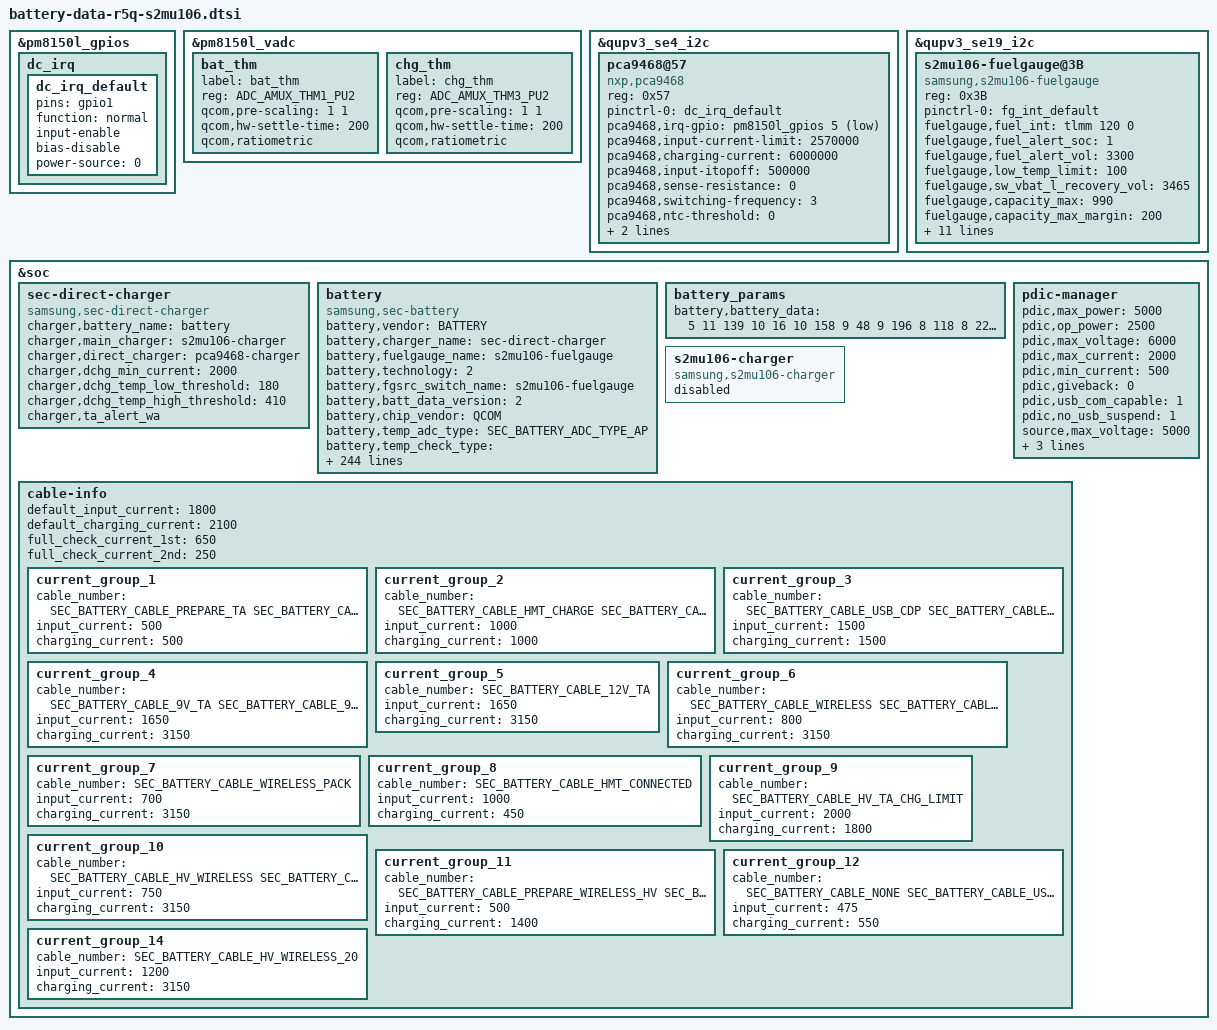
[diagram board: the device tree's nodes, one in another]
/* Copyright (c) 2014, The Linux Foundation. All rights reserved.
 *
 * This program is free software; you can redistribute it and/or modify
 * it under the terms of the GNU General Public License version 2 and
 * only version 2 as published by the Free Software Foundation.
 *
 * This program is distributed in the hope that it will be useful,
 * but WITHOUT ANY WARRANTY; without even the implied warranty of
 * MERCHANTABILITY or FITNESS FOR A PARTICULAR PURPOSE.  See the
 * GNU General Public License for more details.
 */

#include <dt-bindings/battery/sec_battery_param_define.h>

&pm8150l_gpios {
	dc_irq { /* DC_IRQ_N */
		dc_irq_default: dc_irq_default {
			pins = "gpio1";
			function = "normal";
			input-enable;
			bias-disable;
			power-source = <0>;
		};
	};
};

&pm8150l_vadc {
	bat_thm { /* AMUX_1 */
		label = "bat_thm";
		reg = <ADC_AMUX_THM1_PU2>;
		qcom,pre-scaling = <1 1>;
		qcom,hw-settle-time = <200>;
		qcom,ratiometric;
	};
	chg_thm { /* AMUX_3 */
		label = "chg_thm";
		reg = <ADC_AMUX_THM3_PU2>;
		qcom,pre-scaling = <1 1>;
		qcom,hw-settle-time = <200>;
		qcom,ratiometric;
	};
};

&qupv3_se4_i2c {
	status = "okay";

	pca9468@57 {
		compatible = "nxp,pca9468";
		reg = <0x57>;
		pinctrl-names = "default";
		pinctrl-0 = <&dc_irq_default>;

		pca9468,irq-gpio = <&pm8150l_gpios 5 GPIO_ACTIVE_LOW>; /* DC_IRQ */
		pca9468,input-current-limit = <2570000>; /* 2.57A */
		pca9468,charging-current = <6000000>; /* 6A */
		pca9468,input-itopoff = <500000>; /* 500mA */
		pca9468,sense-resistance = <0>; /* 5mOhm */
		pca9468,switching-frequency = <3>; /* 980KHz */
		pca9468,ntc-threshold = <0>; /* disable */
		pca9468,chg_gpio_en = <&pm8150l_gpios 2 0>; /* DC_CPEN */
		pca9468,ta-mode = <1>; /* 2:1 charging mode */
	};
};

&qupv3_se19_i2c {
	status = "ok";

	s2mu106-fuelgauge@3B {
		compatible = "samsung,s2mu106-fuelgauge";
		reg = <0x3B>;
		pinctrl-names = "default";
		pinctrl-0 = <&fg_int_default>;
		fuelgauge,fuel_int = <&tlmm 120 0>;
		fuelgauge,fuel_alert_soc = <1>;
		fuelgauge,fuel_alert_vol = <3300>;
		fuelgauge,low_temp_limit = <100>;
		fuelgauge,sw_vbat_l_recovery_vol = <3465>;
		fuelgauge,capacity_max = <990>;
		fuelgauge,capacity_max_margin = <200>;
		fuelgauge,capacity_min = <0>;
		fuelgauge,capacity_calculation_type = <28>;
		fuelgauge,capacity_full = <4370>;
		fuelgauge,type_str = "SDI";
		fuelgauge,fg_log_enable = <1>;
		fuelgauge,low_voltage_limit_lowtemp = <3100>;
		fuelgauge,i_socr_coeff = <80>;
		fuelgauge,low_t_compen_coeff = <180>;

		fuelgauge,ttf_capacity = <4370>;
		fuelgauge,cv_data = <
			2488	829	1809
			2409	832	1796
			2327	837	1769
			2272	840	1743
			2182	846	1721
			2104	850	1690
			2038	854	1670
			1950	859	1640
			1904	861	1622
			1838	865	1594
			1797	867	1576
			1749	870	1560
			1703	873	1531
			1683	873	1525
			1667	875	1515
			1660	875	1512
			1653	876	1509
			1615	878	1502
			1580	880	1483
			1553	881	1463
			1544	882	1458
			1520	883	1451
			1477	886	1424
			1431	888	1409
			1396	891	1383
			1347	894	1361
			1299	896	1332
			1267	898	1315
			1231	902	1288
			1202	904	1263
			1148	906	1243
			1109	909	1213
			1067	911	1185
			1031	914	1156
			1013	915	1140
			975	917	1111
			961	919	1084
			921	921	1064
			892	923	1038
			887	923	1019
			863	925	1004
			833	927	976
			808	929	946
			787	930	918
			780	931	904
			764	932	895
			744	934	864
			730	935	846
			715	936	828
			693	937	800
			681	938	783
			666	940	752
			651	941	735
			640	942	712
			628	945	697
			622	946	679
			618	947	664
			600	950	646
			596	951	627
			589	953	614
			584	953	601
			576	956	572
			577	957	553
			562	958	535
			511	968	506
			505	969	487
			493	971	464
			492	972	435
			484	973	417
			480	975	398
			474	976	380
			470	977	364
			462	977	355
			456	978	336
			452	979	329
			446	981	303
			437	982	282
			429	984	255
			423	985	242
			422	986	229
			414	987	211
			411	988	199
			405	989	191
			397	990	171
			391	991	140
			387	992	126
			384	993	107
			372	995	84
			364	997	54
			356	998	26
			356	998	13
			0	1000	0
			>;
	};
};

&soc {
	sec-direct-charger {
		status = "okay";
		compatible = "samsung,sec-direct-charger";

		charger,battery_name = "battery";
		charger,main_charger = "s2mu106-charger";
		charger,direct_charger = "pca9468-charger";

		charger,dchg_min_current = <2000>;
		charger,dchg_temp_low_threshold = <180>;
		charger,dchg_temp_high_threshold = <410>;

		charger,ta_alert_wa;
	};

	battery {
		status = "okay";
		compatible = "samsung,sec-battery";
		pinctrl-names = "default";
		battery,vendor = "BATTERY";
		battery,charger_name = "sec-direct-charger";
		battery,fuelgauge_name = "s2mu106-fuelgauge";
		battery,technology = <2>; /* POWER_SUPPLY_TECHNOLOGY_LION */
		battery,fgsrc_switch_name = "s2mu106-fuelgauge"; /* Fuelgauge voltage source */

		battery,batt_data_version = <2>;

		battery,chip_vendor = "QCOM";
		battery,temp_adc_type = <SEC_BATTERY_ADC_TYPE_AP>;

		battery,temp_check_type = <SEC_BATTERY_TEMP_CHECK_ADC>;
		battery,usb_temp_check_type = <SEC_BATTERY_TEMP_CHECK_NONE>;
		battery,chg_temp_check_type = <SEC_BATTERY_TEMP_CHECK_ADC>;
		battery,wpc_temp_check_type = <SEC_BATTERY_TEMP_CHECK_NONE>;
		battery,dchg_temp_check_type = <SEC_BATTERY_TEMP_CHECK_ADC>;

		battery,thermal_source = <SEC_BATTERY_THERMAL_SOURCE_ADC>;
		battery,usb_thermal_source = <SEC_BATTERY_THERMAL_SOURCE_ADC>;
		battery,chg_thermal_source = <SEC_BATTERY_THERMAL_SOURCE_ADC>;
		battery,wpc_thermal_source = <SEC_BATTERY_THERMAL_SOURCE_ADC>;
		battery,dchg_thermal_source = <SEC_BATTERY_THERMAL_SOURCE_CHG_ADC>;

		battery,polling_time = <10 30 30 30 3600>;

		battery,temp_table_adc = <250021 290527 319506 370285 427378
						492246 564673 645166 732968 825659
						924340 1024967 1126957 1226048 1321129
						1408985 1488245 1558510 1618036 1668566
						1708520 1740765 1750929>;
		battery,temp_table_data = <900 850 800 750 700
						650 600 550 500 450
						400 350 300 250 200
						150 100 50 0 (-50)
						(-100) (-150) (-200)>;

		battery,usb_temp_table_adc = <128092 155146 181746 212586 249610
						293641 346668 396929 460315 531033
						612607 708866 815008 922383 1030341
						1141067 1248355 1350324 1446150 1530838
						1604346 1665116 1714272>;
		battery,usb_temp_table_data = <900 850 800 750 700
						650 600 550 500 450
						400 350 300 250 200
						150 100 50 0 (-50)
						(-100) (-150) (-200)>;

		battery,chg_temp_table_adc = <107508 131686 159118 188746 223508
						262961 307691 361916 429577 488076
						586007 680146 775042 886814 995479
						1077371 1208541 1306638 1413804 1506271
						1581235 1644636 1687932>;
		battery,chg_temp_table_data = <900 850 800 750 700
						650 600 550 500 450
						400 350 300 250 200
						150 100 50 0 (-50)
						(-100) (-150) (-200)>;

		battery,wpc_temp_table_adc = <129022 155579 182115 213192 249978
						294052 346625 396929 460683 530860
						612175 708282 814035 921474 1028914
						1139553 1246214 1348248 1443900 1528741
						1602248 1661591 1712499>;
		battery,wpc_temp_table_data = <900 850 800 750 700
						650 600 550 500 450
						400 350 300 250 200
						150 100 50 0 (-50)
						(-100) (-150) (-200)>;

		battery,dchg_temp_table_adc = <110882 138414 166566 194718 234600
						276828 326094 387090 448086 525504
						607614 696762 792948 893826 999396
						1107312 1210536 1304376 1393524 1473288
						1543668 1602318 1651584>;
		battery,dchg_temp_table_data = <900 850 800 750 700
						650 600 550 500 450
						400 350 300 250 200
						150 100 50 0 (-50)
						(-100) (-150) (-200)>;

		battery,wireless_cc_cv = <85>;
		battery,wpc_det = <&pm8150l_gpios 1 GPIO_ACTIVE_HIGH>; /* WPC_DET */
		battery,wpc_en = <&expander_gpios 3 0>; /* WPC_EN */
		battery,adc_check_count = <5>;

		battery,cable_check_type = <SEC_BATTERY_CABLE_CHECK_PSY>;
		battery,cable_source_type = <SEC_BATTERY_CABLE_SOURCE_EXTERNAL>;
		battery,polling_type = <SEC_BATTERY_MONITOR_ALARM>;
		battery,monitor_initial_count = <0>;

		battery,battery_check_type = <0>; /* SEC_BATTERY_CHECK_NONE */
		battery,check_count = <0>;
		battery,check_adc_max = <1440>;
		battery,check_adc_min = <0>;

		battery,ovp_uvlo_check_type = <SEC_BATTERY_OVP_UVLO_CHGPOLLING>;

		battery,temp_check_count = <1>;
		battery,temp_highlimit_threshold_event = <700>;
		battery,temp_highlimit_recovery_event = <680>;
		battery,temp_high_threshold_event = <500>;
		battery,temp_high_recovery_event = <480>;
		battery,temp_low_threshold_event = <0>;
		battery,temp_low_recovery_event = <20>;
		battery,temp_highlimit_threshold_normal = <700>;
		battery,temp_highlimit_recovery_normal = <680>;
		battery,temp_high_threshold_normal = <500>;
		battery,temp_high_recovery_normal = <480>;
		battery,temp_low_threshold_normal = <0>;
		battery,temp_low_recovery_normal = <20>;
		battery,temp_highlimit_threshold_lpm = <700>;
		battery,temp_highlimit_recovery_lpm = <680>;
		battery,temp_high_threshold_lpm = <500>;
		battery,temp_high_recovery_lpm = <480>;
		battery,temp_low_threshold_lpm = <0>;
		battery,temp_low_recovery_lpm = <20>;
		battery,wpc_high_threshold_normal = <450>;
		battery,wpc_high_recovery_normal = <430>;
		battery,wpc_low_threshold_normal = <0>;
		battery,wpc_low_recovery_normal = <20>;
		battery,tx_high_threshold = <450>;
		battery,tx_high_recovery = <400>;
		battery,tx_low_threshold = <0>;
		battery,tx_low_recovery = <50>;
		battery,full_check_type = <SEC_BATTERY_FULLCHARGED_FG_CURRENT>;
		battery,full_check_type_2nd = <SEC_BATTERY_FULLCHARGED_FG_CURRENT>;
		battery,full_check_count = <1>;
		battery,chg_gpio_full_check = <0>;
		battery,chg_polarity_full_check = <1>;

		battery,chg_high_temp = <460>;
		battery,chg_high_temp_recovery = <440>;
		battery,dchg_high_temp = <560>;
		battery,dchg_high_temp_recovery = <400>;
		battery,dchg_high_batt_temp = <400>;
		battery,dchg_high_batt_temp_recovery = <380>;
		battery,chg_input_limit_current = <1000>;
		battery,chg_charging_limit_current = <1700>;
		battery,dchg_input_limit_current = <1000>;
		battery,dchg_charging_limit_current = <2000>;

		battery,wpc_temp_control_source = <TEMP_CONTROL_SOURCE_BAT_THM>;
		battery,wpc_high_temp = <380>;
		battery,wpc_high_temp_recovery = <360>;
		battery,wpc_input_limit_current = <600>;
		battery,wpc_charging_limit_current = <1000>;
		battery,wpc_temp_lcd_on_control_source = <TEMP_CONTROL_SOURCE_BAT_THM>;
		battery,wpc_lcd_on_high_temp = <380>;
		battery,wpc_lcd_on_high_temp_rec = <360>;
		battery,wpc_lcd_on_input_limit_current = <450>;

		battery,wpc_store_high_temp = <360>;
		battery,wpc_store_high_temp_recovery = <340>;
		battery,wpc_store_charging_limit_current = <400>;
		battery,wpc_store_lcd_on_high_temp = <360>;
		battery,wpc_store_lcd_on_high_temp_rec = <300>;
		battery,wpc_store_lcd_on_charging_limit_current = <400>;

		battery,ta_alert_wa;

		battery,sleep_mode_limit_current = <800>;
		battery,wc_full_input_limit_current = <100>;

		battery,mix_high_temp = <420>;
		battery,mix_high_chg_temp = <500>;
		battery,mix_high_temp_recovery = <390>;

		battery,full_condition_type = <(SEC_BATTERY_FULL_CONDITION_NOTIMEFULL | SEC_BATTERY_FULL_CONDITION_VCELL)>;
		battery,full_condition_soc = <93>;
		battery,full_condition_vcell = <4300>;

		battery,recharge_check_count = <1>;
		battery,recharge_condition_type = <SEC_BATTERY_RECHARGE_CONDITION_VCELL>;
		battery,recharge_condition_soc = <98>;
		battery,recharge_condition_vcell = <4280>;

		battery,charging_total_time = <14400>;
		battery,hv_charging_total_time = <10800>;
		battery,normal_charging_total_time = <18000>;
		battery,usb_charging_total_time = <36000>;
		battery,recharging_total_time = <5400>;
		battery,charging_reset_time = <0>;

		battery,chg_float_voltage = <4350>;
		battery,chg_ocp_current = <6200>;
		battery,chg_ocp_dtc = <100>;

		battery,pre_afc_work_delay = <2000>;
		battery,pre_wc_afc_work_delay = <4000>;
		battery,pre_afc_input_current = <500>;
		battery,pre_wc_afc_input_current = <500>;
		battery,prepare_ta_delay = <0>; /* msec */

		battery,swelling_high_temp_block = <410>;
		battery,swelling_high_temp_recov = <390>;
		battery,swelling_low_temp_block_1st = <150>;
		battery,swelling_low_temp_recov_1st = <170>;
		battery,swelling_low_temp_block_2nd = <50>;
		battery,swelling_low_temp_recov_2nd = <70>;
		battery,swelling_low_temp_3rd_ctrl;
		battery,swelling_low_temp_block_3rd = <180>;
		battery,swelling_low_temp_recov_3rd = <200>;

		battery,swelling_low_temp_current = <1000>;	/* 0.24C */
		battery,swelling_low_temp_current_2nd = <400>;	/* 0.1C */
		battery,swelling_low_temp_current_3rd = <3100>;	/* 0.72C */
		battery,swelling_low_temp_topoff = <250>;	/* 0.05C */
		battery,swelling_high_temp_current = <1550>;	/* 0.36C */
		battery,swelling_high_temp_topoff = <250>;	/* 0.05C */
		battery,swelling_wc_high_temp_current = <1000>;	/* 0.24C */
		battery,swelling_wc_low_temp_current = <1000>;	/* 0.24C */
		battery,swelling_wc_low_temp_current_2nd = <400>;	/* 0.1C */
		battery,swelling_wc_low_temp_current_3rd = <3000>;	/* 0.72C */

		battery,swelling_drop_float_voltage = <4150>;
		battery,swelling_high_rechg_voltage = <4000>;
		battery,swelling_low_rechg_thr = <150>;

		battery,siop_input_limit_current = <1200>;
		battery,siop_charging_limit_current = <1000>;
		battery,siop_hv_input_limit_current = <700>;
		battery,siop_hv_input_limit_current_2nd = <450>;
		battery,siop_hv_charging_limit_current = <1000>;
		battery,siop_apdo_input_limit_current = <1200>;
		battery,siop_apdo_charging_limit_current = <2000>;

		battery,siop_wireless_input_limit_current = <600>;
		battery,siop_wireless_charging_limit_current = <850>;
		battery,siop_hv_wireless_input_limit_current = <600>;
		battery,siop_hv_wireless_charging_limit_current = <850>;
		battery,siop_store_hv_wireless_input_limit_current = <450>;

		battery,wireless_otg_input_current = <900>;

		battery,ttf_hv_charge_current = <3650>;
		battery,ttf_hv_12v_wireless_charge_current = <2450>;
		battery,ttf_hv_wireless_charge_current = <1450>;
		battery,ttf_wireless_charge_current = <900>;
		battery,ttf_dc25_charge_current = <6600>;
		battery,ttf_dc45_charge_current = <7500>;
		battery,ttf_normal_charge_current = <2190>;

		battery,rp_current_rp1 = <500>;
		battery,rp_current_rp2 = <1500>;
		battery,rp_current_rp3 = <3000>;
		battery,rp_current_rdu_rp3 = <2100>;
		battery,rp_current_abnormal_rp3 = <1800>;

		battery,pd_charging_charge_power = <15000>;
		battery,max_charging_current = <3150>;
		battery,max_charging_charge_power = <45000>; /* 45W */

		/* cycle, chg_float_voltage, recharge_condition_vcell, full_condition_vcell, full_condition_soc, step charging condition */
		battery,age_data = <0 4350 4280 4300 93 45
				300 4330 4260 4280 92 45
				400 4310 4240 4260 91 45
				700 4290 4220 4240 90 45
				1000 4240 4170 4190 89 45>;

		battery,health_condition = <
			/* CYCLE ASOC */
			900 0	/* GOOD */
			1200 0 /* NORMAL */
			1500 0 /* AGED */
			>;

		/* step charging option */
		battery,step_charging_type = <0>;
		battery,step_charging_charge_power = <12000>;
		battery,step_charging_condition = <45 100>;
		battery,step_charging_condition_curr = <3150 3150>;
		battery,step_charging_current = <3150 3150>;
		battery,step_charging_float_voltage = <4150 4350>;

		/* direct step charging option */
		battery,dc_step_chg_type = <0x6B>; /* origin(0x6B), soc option is temporary removed */
		battery,dc_step_chg_charge_power = <22000>;
		battery,dc_step_chg_step = <4>;
		battery,dc_step_chg_cond_vol = <3950 4050 4300 4350>; /* STEP_CHARGING_CONDITION_VOLTAGE */ 
		battery,dc_step_chg_cond_iin = <3150 2300 1950 0>; /* STEP_CHARGING_CONDITION_INPUT_CURRENT */
		battery,dc_step_chg_iin_check_cnt = <3>;
		battery,dc_step_chg_cond_soc = <5 30 76 100>; /* STEP_CHARGING_CONDITION_SOC */
		battery,dc_step_chg_val_vfloat = <3950 4050 4300 4350>; /* STEP_CHARGING_CONDITION_FLOAT_VOLTAGE */
		battery,dc_step_chg_val_iout = <7500 6300 4600 3900>;

		battery,max_input_voltage = <9000>; /* mV */
		battery,max_input_current = <3000>;  /* mA */

		battery,enable_sysovlo_irq;
		battery,enable_noise_wa;

		battery,standard_curr = <3150>;
		battery,expired_time = <10800>;
		battery,recharging_expired_time = <5400>;

		battery,battery_full_capacity = <4400>;
		battery,cisd_max_voltage_thr = <5000>; /* batttery ovp dettection voltage */
		battery,cisd_alg_index = <8>;
		battery,ignore_cisd_index = <0 960>; /* Do not use AFC_FAIL to DROP_VALUE */
		battery,ignore_cisd_index_d = <0 120>; /* Do not use AFC_FAIL_PER_DAY to DROP_VALUE_PER_DAY */

		battery,tx_stop_capacity = <30>;
		battery,tx_minduty_default = <20>;
		battery,tx_minduty_5V = <50>;

		io-channels = <&pm8150l_vadc ADC_AMUX_THM1_PU2>, <&pm8150l_vadc ADC_AMUX_THM3_PU2>, <&pm8150l_vadc ADC_GPIO1_PU2>;
		io-channel-names = "adc-temp", "adc-chg-temp", "adc-usb-temp";
	};

	battery_params {
		battery,battery_data =
			<
			/***** battery data for 4.35 *****/
			/* battery,battery_table3 */
			5 11 139 10 16 10 158 9 48 9
			196 8 118 8 227 7 173 7 65 7
			237 6 182 6 139 6 104 6 76 6
			41 6 0 6 218 5 156 5 131 5
			156 4 133 1 106 8 0 8 150 7
			44 7 194 6 89 6 239 5 133 5
			27 5 177 4 71 4 222 3 116 3
			10 3 160 2 54 2 204 1 99 1
			249 0 143 0 37 0 223 15

			/* battery,battery_table4 */
			10 10 10 10 26 26 25 24 24 24
			23 23 23 24 25 26 27 28 29 31
			36 154

			/* battery,batcap */
			0xE8 0x44 0x56 0x0A /* [0x0E] [0x0F] [0x10] [0x11] */
			/* battery,accum */ 
			0x00 0x08 /* [0x44] [0x45] */

			/* battery,soc_arr_val */
			10517 10000 9483 8966 8450 7933 7416 6899 6382 5866
			5349 4832 4315 3798 3282 2765 2248 1731 1214 698
			181 (-161)

			/* battery,ocv_arr_val */
			43776 43178 42579 42019 41484 40959 40575 39857 39596 39069
			38655 38390 38178 38010 37873 37702 37499 37313 37011 36890
			35763 31900

			/* battery,tunning */
			0x00

			/***** battery data for 4.33 *****/
			/* battery,battery_table3 */
			5 11 139 10 16 10 158 9 48 9
			196 8 118 8 227 7 173 7 65 7
			237 6 182 6 139 6 104 6 76 6
			41 6 0 6 218 5 156 5 131 5
			156 4 133 1 158 8 50 8 197 7
			89 7 236 6 128 6 20 6 167 5
			59 5 206 4 98 4 246 3 137 3
			29 3 176 2 68 2 216 1 107 1
			255 0 146 0 38 0 222 15

			/* battery,battery_table4 */
			10 10 10 10 26 26 25 24 24 24
			23 23 23 24 25 26 27 28 29 31
			36 154

			/* battery,batcap */
			0x68 0x42 0x9A 0x10 /* [0x0E] [0x0F] [0x10] [0x11] */
			/* battery,accum */
			0x00 0x08 /* [0x44] [0x45] */

			/* battery,soc_arr_val */
			10772 10242 9713 9184 8654 8125 7596 7066 6537 6008
			5478 4949 4420 3890 3361 2832 2303 1773 1244 715
			185 (-165)

			/* battery,ocv_arr_val */
			43776 43178 42579 42019 41484 40959 40575 39857 39596 39069
			38655 38390 38178 38010 37873 37702 37499 37313 37011 36890
			35763 31900

			/* battery,tunning */
			0x00

			/***** battery data for 4.31 *****/
			/* battery,battery_table3 */
			5 11 139 10 16 10 158 9 48 9
			196 8 118 8 227 7 173 7 65 7
			237 6 182 6 139 6 104 6 76 6
			41 6 0 6 218 5 156 5 131 5
			156 4 133 1 196 8 86 8 232 7
			121 7 11 7 157 6 46 6 192 5
			82 5 228 4 117 4 7 4 153 3
			43 3 188 2 78 2 224 1 113 1
			3 1 149 0 39 0 222 15

			/* battery,battery_table4 */
			10 10 10 10 26 26 25 24 24 24
			23 23 23 24 25 26 27 28 29 31
			36 154

			/* battery,batcap */
			0x50 0x41 0x54 0x10 /* [0x0E] [0x0F] [0x10] [0x11] */
			/* battery,accum */
			0x00 0x08 /* [0x44] [0x45] */

			/* battery,soc_arr_val */
			10957 10419 9881 9342 8804 8265 7727 7188 6650 6111
			5573 5035 4496 3958 3419 2881 2342 1804 1265 727
			188 (-168)

			/* battery,ocv_arr_val */
			43776 43178 42579 42019 41484 40959 40575 39857 39596 39069
			38655 38390 38178 38010 37873 37702 37499 37313 37011 36890
			35763 31900

			/* battery,tunning */
			0x00

			/***** battery data for 4.29 *****/
			/* battery,battery_table3 */
			5 11 139 10 16 10 158 9 48 9
			196 8 118 8 227 7 173 7 65 7
			237 6 182 6 139 6 104 6 76 6
			41 6 0 6 218 5 156 5 131 5
			156 4 133 1 235 8 123 8 11 8
			155 7 43 7 186 6 74 6 218 5
			106 5 250 4 137 4 25 4 169 3
			57 3 201 2 88 2 232 1 120 1
			8 1 151 0 39 0 221 15

			/* battery,battery_table4 */
			10 10 10 10 26 26 25 24 24 24
			23 23 23 24 25 26 27 28 29 31
			36 154

			/* battery,batcap */
			0x38 0x40 0x0E 0x10 /* [0x0E] [0x0F] [0x10] [0x11] */
			/* battery,accum */
			0x00 0x08 /* [0x44] [0x45] */

			/* battery,soc_arr_val */
			11150 10602 10054 9506 8958 8410 7862 7315 6767 6219
			5671 5123 4575 4027 3479 2931 2383 1835 1288 740
			192 (-170)

			/* battery,ocv_arr_val */
			43776 43178 42579 42019 41484 40959 40575 39857 39596 39069
			38655 38390 38178 38010 37873 37702 37499 37313 37011 36890
			35763 31900

			/* battery,tunning */
			0x00

			/***** battery data for 4.24 *****/
			/* battery,battery_table3 */
			5 11 139 10 16 10 158 9 48 9
			196 8 118 8 227 7 173 7 65 7
			237 6 182 6 139 6 104 6 76 6
			41 6 0 6 218 5 156 5 131 5
			156 4 133 1 75 9 214 8 97 8
			236 7 119 7 2 7 142 6 25 6
			164 5 47 5 186 4 69 4 208 3
			91 3 230 2 113 2 253 1 136 1
			19 1 158 0 41 0 220 15

			/* battery,battery_table4 */
			10 10 10 10 26 26 25 24 24 24
			23 23 23 24 25 26 27 28 29 31
			36 154

			/* battery,batcap */
			0x08 0x3E 0x82 0x0F /* [0x0E] [0x0F] [0x10] [0x11] */
			/* battery,accum */
			0x00 0x08 /* [0x44] [0x45] */

			/* battery,soc_arr_val */
			11616 11045 10474 9904 9333 8762 8191 7620 7050 6479
			5908 5337 4766 4195 3625 3054 2483 1912 1341 771
			200 (-178)

			/* battery,ocv_arr_val */
			43776 43178 42579 42019 41484 40959 40575 39857 39596 39069
			38655 38390 38178 38010 37873 37702 37499 37313 37011 36890
			35763 31900

			/* battery,tunning */
			0x00
			>;

	};

	pdic-manager {
		/* sink */
		pdic,max_power = <5000>;
		pdic,op_power = <2500>;
		pdic,max_voltage = <6000>;
		pdic,max_current = <2000>;
		pdic,min_current = <500>;

		pdic,giveback = <0>;
		pdic,usb_com_capable = <1>;
		pdic,no_usb_suspend = <1>;

		/* source */
		source,max_voltage = <5000>;
		source,min_voltage = <4000>;
		source,max_power = <2500>;

		/* sink cap */
		sink,capable_max_voltage = <9000>;
	};

	s2mu106-charger {
		status = "disable";
		compatible = "samsung,s2mu106-charger";
	};

/* sec_battery_cable
 *   0	UNKNOWN,
 *   1	NONE,
 *   2	PREPARE_TA,
 *   3	TA,
 *   4	USB,
 *   5	USB_CDP,
 *   6	9V_TA,
 *   7	9V_ERR,
 *   8	9V_UNKNOWN,
 *   9	12V_TA,
 *  10	WIRELESS,
 *  11	HV_WIRELESS,
 *  12	PMA_WIRELESS,
 *  13	WIRELESS_PACK,
 *  14	CABLE_WIRELESS_HV_PACK,
 *  15	WIRELESS_STAND,
 *  16	WIRELESS_HV_STAND,
 *  17	QC20,
 *  18	QC30,
 *  19	PDIC,
 *  20	UARTOFF,
 *  21	OTG,
 *  22	LAN_HUB,
 *  23	POWER_SHARING,
 *  24	HMT_CONNECTED,
 *  25	HMT_CHARGE,
 *  26	HV_TA_CHG_LIMIT,
 *  27	WIRELESS_VEHICLE,
 *  28	WIRELESS_HV_VEHICLE,
 *  29	PREPARE_WIRELESS_HV,
 *  30  TIMEOUT,
 *  31  SMART_OTG,
 *  32  SMART_NOTG,
 *  33  WIRELESS_TX,
 *  34	HV_WIRELESS_20,
 *  35	HV_WIRELESS_20_LIMIT,
 *  36	WIRELESS_FAKE,
 *  37  PREPARE_WIRELESS_20,
 *  38	CABLE_PDIC_APDO,
 *  39	CABLE_MAX,
 */
	cable-info {
		default_input_current = <1800>;
		default_charging_current = <2100>;
		full_check_current_1st = <650>;
		full_check_current_2nd = <250>;

		current_group_1 {
			cable_number = <
				SEC_BATTERY_CABLE_PREPARE_TA
				SEC_BATTERY_CABLE_PDIC
				SEC_BATTERY_CABLE_OTG
				SEC_BATTERY_CABLE_LAN_HUB
				SEC_BATTERY_CABLE_POWER_SHARING>;
			input_current = <500>;
			charging_current = <500>;
		};
		current_group_2 {
			cable_number = <
				SEC_BATTERY_CABLE_HMT_CHARGE
				SEC_BATTERY_CABLE_SMART_OTG>;
			input_current = <1000>;
			charging_current = <1000>;
		};
		current_group_3 {
			cable_number = <
				SEC_BATTERY_CABLE_USB_CDP
				SEC_BATTERY_CABLE_SMART_NOTG>;
			input_current = <1500>;
			charging_current = <1500>;
		};
		current_group_4 {
			cable_number = <
				SEC_BATTERY_CABLE_9V_TA
				SEC_BATTERY_CABLE_9V_ERR
				SEC_BATTERY_CABLE_9V_UNKNOWN
				SEC_BATTERY_CABLE_QC20
				SEC_BATTERY_CABLE_QC30>;
			input_current = <1650>;
			charging_current = <3150>;
		};
		current_group_5 {
			cable_number = <SEC_BATTERY_CABLE_12V_TA>;
			input_current = <1650>;
			charging_current = <3150>;
		};
		current_group_6 {
			cable_number = <
				SEC_BATTERY_CABLE_WIRELESS
				SEC_BATTERY_CABLE_PMA_WIRELESS
				SEC_BATTERY_CABLE_WIRELESS_STAND
				SEC_BATTERY_CABLE_WIRELESS_VEHICLE
				SEC_BATTERY_CABLE_WIRELESS_TX
				SEC_BATTERY_CABLE_WIRELESS_FAKE>;
			input_current = <800>;
			charging_current = <3150>;
		};
		current_group_7 {
			cable_number = <SEC_BATTERY_CABLE_WIRELESS_PACK>;
			input_current = <700>;
			charging_current = <3150>;
		};
		current_group_8 {
			cable_number = <SEC_BATTERY_CABLE_HMT_CONNECTED>;
			input_current = <1000>;
			charging_current = <450>;
		};
		current_group_9 {
			cable_number = <SEC_BATTERY_CABLE_HV_TA_CHG_LIMIT>;
			input_current = <2000>;
			charging_current = <1800>;
		};
		current_group_10 {
			cable_number = <
				SEC_BATTERY_CABLE_HV_WIRELESS
				SEC_BATTERY_CABLE_WIRELESS_HV_PACK
				SEC_BATTERY_CABLE_WIRELESS_HV_STAND
				SEC_BATTERY_CABLE_WIRELESS_HV_VEHICLE
				SEC_BATTERY_CABLE_HV_WIRELESS_20_LIMIT>;
			input_current = <750>;
			charging_current = <3150>;
		};
		current_group_11 {
			cable_number = <
				SEC_BATTERY_CABLE_PREPARE_WIRELESS_HV
				SEC_BATTERY_CABLE_PREPARE_WIRELESS_20>;
			input_current = <500>;
			charging_current = <1400>;
		};
		current_group_12 {
			cable_number = <
				SEC_BATTERY_CABLE_NONE
				SEC_BATTERY_CABLE_USB
				SEC_BATTERY_CABLE_TIMEOUT>;
			input_current = <475>;
			charging_current = <550>;
		};
		current_group_14 {
			cable_number = <SEC_BATTERY_CABLE_HV_WIRELESS_20>;
			input_current = <1200>;
			charging_current = <3150>;
		};
	};
};
